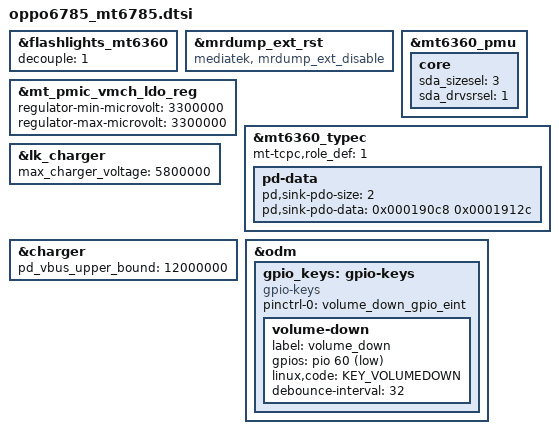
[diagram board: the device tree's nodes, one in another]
// SPDX-License-Identifier: GPL-2.0
/*
 * Board specific overrides of the MT6785 base device tree,
 * shared by all oppo6785 projects.
 */

#include <dt-bindings/gpio/gpio.h>
#include <dt-bindings/input/input.h>

&flashlights_mt6360 {
	decouple = <1>;
};

&mrdump_ext_rst {
	compatible = "mediatek, mrdump_ext_disable";
};

&mt6360_pmu {
	core {
		sda_sizesel = <3>;
		sda_drvsrsel = <1>;
	};
};

&mt_pmic_vmch_ldo_reg {
	regulator-min-microvolt = <3300000>;
	regulator-max-microvolt = <3300000>;
};

&mt6360_typec {
	mt-tcpc,role_def = <1>;

	pd-data {
		pd,sink-pdo-size = <2>;
		pd,sink-pdo-data = <0x000190c8 0x0001912c>;
	};
};

&lk_charger {
	max_charger_voltage = <5800000>;
};

&charger {
	pd_vbus_upper_bound = <12000000>;
};

/*
 * Volume up is the PMIC home key (kpd-sw-rstkey), volume down is wired
 * to GPIO60 instead of the keypad matrix.
 */
&odm {
	gpio_keys: gpio-keys {
		compatible = "gpio-keys";
		pinctrl-names = "default";
		pinctrl-0 = <&volume_down_gpio_eint>;

		volume-down {
			label = "volume_down";
			gpios = <&pio 60 GPIO_ACTIVE_LOW>;
			linux,code = <KEY_VOLUMEDOWN>;
			debounce-interval = <32>;
		};
	};
};

